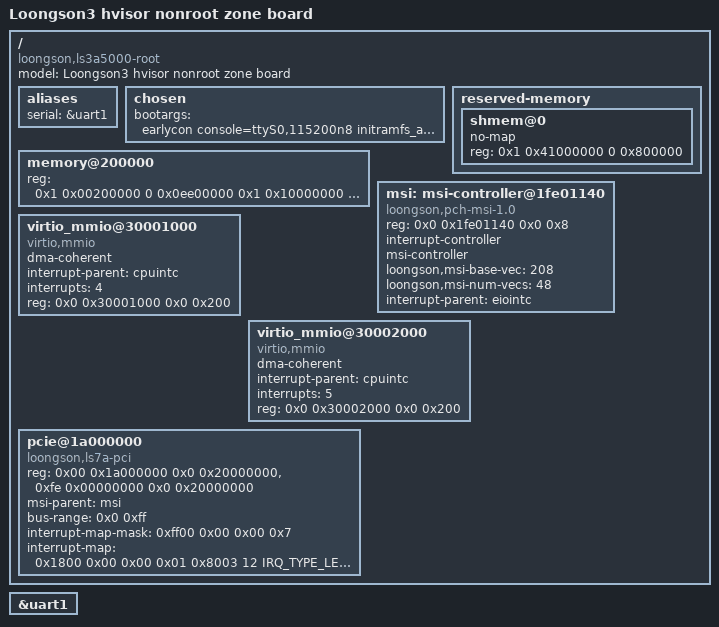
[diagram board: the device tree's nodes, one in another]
// SPDX-License-Identifier: GPL-2.0
/*
* Copyright (C) 2023 Loongson Technology Corporation Limited
* Modified for hvisor by wheatfox(wheatfox17@icloud.com) syswonder.org 2024
*/

/dts-v1/;

#include "loongson-3a5000.dtsi"


&uart1 {
	status = "okay";
	// set the above 'uart1' to 'uart0' if you don't have a COM connection right now
};


/ {
	compatible = "loongson,ls3a5000-root", "loongson,ls3a5000";
	model = "Loongson3 hvisor nonroot zone board";
	
	aliases {
		serial = &uart1;
	};
	
	chosen {
		// initramfs
		bootargs = "earlycon console=ttyS0,115200n8 initramfs_async=false rootwait debug loglevel=8 earlyprintk nohlt";
		
		// SSD root, a {zone_name}-disk.ext4 virtio blk file on SSD root_hvisor partition
		// bootargs = "earlycon console=ttyS0,115200n8 rootwait root=/dev/vda rw";
	};
	
	memory@200000 {
		device_type = "memory";
		reg = <0x1 0x00200000 0 0x0ee00000
		0x1 0x10000000 0 0x10000000
		0x1 0x41000000 0 0x800000
		>;
	};
	
	reserved-memory {
		#address-cells = <0x02>;
		#size-cells = <0x02>;
		ranges;
		shmem@0 {
			no-map;
			reg = <0x1 0x41000000 0 0x800000>;
		};
	};
	
	msi: msi-controller@1fe01140 {
		compatible = "loongson,pch-msi-1.0";
		reg = <0x0 0x1fe01140 0x0 0x8>;
		interrupt-controller;
		#interrupt-cells = <1>;
		msi-controller;
		loongson,msi-base-vec = <208>;
		loongson,msi-num-vecs = <48>;// [64-111(48),112-159(48),160-207(48),208-255(48)]
		interrupt-parent = <&eiointc>;
		phandle = <0x8004>;
	};
	
	// virtio console
	virtio_mmio@30001000 {
		dma-coherent;
		compatible = "virtio,mmio";
		interrupt-parent = <&cpuintc>;
		interrupts = <4>;// = hwirq
		reg = <0x0 0x30001000 0x0 0x200>;
		status = "okay";
	};
	// virtio blk
	virtio_mmio@30002000 {
		dma-coherent;
		compatible = "virtio,mmio";
		// interrupt-parent = <&cpuintc>;
		// interrupts = <5>;// = hwirq
		interrupt-parent = <&cpuintc>;
		interrupts = <5>;// = hwirq
		reg = <0x0 0x30002000 0x0 0x200>;
		status = "okay";
	};
	
	pcie@1a000000 {
		compatible = "loongson,ls7a-pci";
	
		// configuration space
		reg =
		<0x00 0x1a000000 0x0 0x20000000>,
		<0xfe 0x00000000 0x0 0x20000000>;
	
		#address-cells = <3>;
		#size-cells = <2>;
		device_type = "pci";
		msi-parent = <&msi>;
		bus-range = <0x0 0xff>;
	
		// PCIe resources
		ranges =
		<0x01000000 0x0 0x00008000 0x0 0x18408000 0x0 0x00008000>,// 0x01000000 (IO) [PCIe space base address][CPU space address][size]
		<0x02000000 0x0 0x60000000 0x0 0x60000000 0x0 0x20000000>;// 0x02000000 (MEM) [PCIe space base address][CPU space address][size]
	
		// interrputs
		interrupt-map-mask = <0xff00 0x00 0x00 0x7>;
		interrupt-map =
		<
		0x1800 0x00 0x00 0x01 0x8003 12 IRQ_TYPE_LEVEL_HIGH// 3,0 a
		0x1800 0x00 0x00 0x02 0x8003 13 IRQ_TYPE_LEVEL_HIGH// 3,0 b
	
		0x2000 0x00 0x00 0x01 0x8003 49 IRQ_TYPE_LEVEL_HIGH// 4,0 a 
		0x2100 0x00 0x00 0x01 0x8003 48 IRQ_TYPE_LEVEL_HIGH// 4,1 b 
	
		0x2800 0x00 0x00 0x01 0x8003 51 IRQ_TYPE_LEVEL_HIGH// 5,0 a 
		0x2800 0x00 0x00 0x02 0x8003 51 IRQ_TYPE_LEVEL_HIGH// 5,0 b
		0x2800 0x00 0x00 0x03 0x8003 51 IRQ_TYPE_LEVEL_HIGH// 5,0 c 
		0x2800 0x00 0x00 0x04 0x8003 51 IRQ_TYPE_LEVEL_HIGH// 5,0 d 
	
		0x2900 0x00 0x00 0x01 0x8003 50 IRQ_TYPE_LEVEL_HIGH// 5,1 a 
		0x2900 0x00 0x00 0x02 0x8003 50 IRQ_TYPE_LEVEL_HIGH// 5,1 b 
		0x2900 0x00 0x00 0x03 0x8003 50 IRQ_TYPE_LEVEL_HIGH// 5,1 c 
		0x2900 0x00 0x00 0x04 0x8003 50 IRQ_TYPE_LEVEL_HIGH// 5,1 d 
	
		0x3000 0x00 0x00 0x01 0x8003 29 IRQ_TYPE_LEVEL_HIGH// 6,0 a 
		0x3000 0x00 0x00 0x02 0x8003 29 IRQ_TYPE_LEVEL_HIGH// 6,0 b  
		0x3000 0x00 0x00 0x03 0x8003 29 IRQ_TYPE_LEVEL_HIGH// 6,0 c 
		0x3000 0x00 0x00 0x04 0x8003 29 IRQ_TYPE_LEVEL_HIGH// 6,0 d 
	
		0x3100 0x00 0x00 0x01 0x8003 28 IRQ_TYPE_LEVEL_HIGH// 6,1 a
		0x3100 0x00 0x00 0x02 0x8003 28 IRQ_TYPE_LEVEL_HIGH// 6,1 b
		0x3100 0x00 0x00 0x03 0x8003 28 IRQ_TYPE_LEVEL_HIGH// 6,1 c
		0x3100 0x00 0x00 0x04 0x8003 28 IRQ_TYPE_LEVEL_HIGH// 6,1 d
	
		0x3200 0x00 0x00 0x01 0x8003 23 IRQ_TYPE_LEVEL_HIGH// 6,2 a 
		0x3200 0x00 0x00 0x02 0x8003 23 IRQ_TYPE_LEVEL_HIGH// 6,2 b 
		0x3200 0x00 0x00 0x03 0x8003 23 IRQ_TYPE_LEVEL_HIGH// 6,2 c 
		0x3200 0x00 0x00 0x04 0x8003 23 IRQ_TYPE_LEVEL_HIGH// 6,2 d 
	
		0x3800 0x00 0x00 0x01 0x8003 78 IRQ_TYPE_LEVEL_HIGH// 7,0 a
		0x3800 0x00 0x00 0x02 0x8003 79 IRQ_TYPE_LEVEL_HIGH// 7,0 b
	
		0x4000 0x00 0x00 0x01 0x8003 16 IRQ_TYPE_LEVEL_HIGH// 8,0 a 
		0x4000 0x00 0x00 0x02 0x8003 16 IRQ_TYPE_LEVEL_HIGH// 8,0 b 
		0x4000 0x00 0x00 0x03 0x8003 16 IRQ_TYPE_LEVEL_HIGH// 8,0 c 
		0x4000 0x00 0x00 0x04 0x8003 16 IRQ_TYPE_LEVEL_HIGH// 8,0 d 
	
		0x4800 0x00 0x00 0x01 0x8003 32 IRQ_TYPE_LEVEL_HIGH// 9,0 a
		0x4800 0x00 0x00 0x02 0x8003 32 IRQ_TYPE_LEVEL_HIGH// 9,0 b
		0x4800 0x00 0x00 0x03 0x8003 32 IRQ_TYPE_LEVEL_HIGH// 9,0 c 
		0x4800 0x00 0x00 0x04 0x8003 32 IRQ_TYPE_LEVEL_HIGH// 9,0 d
	
		0x5000 0x00 0x00 0x01 0x8003 33 IRQ_TYPE_LEVEL_HIGH// a,0 a 
		0x5000 0x00 0x00 0x02 0x8003 33 IRQ_TYPE_LEVEL_HIGH// a,0 b  
		0x5000 0x00 0x00 0x03 0x8003 33 IRQ_TYPE_LEVEL_HIGH// a,0 c 
		0x5000 0x00 0x00 0x04 0x8003 33 IRQ_TYPE_LEVEL_HIGH// a,0 d 
	
		0x5800 0x00 0x00 0x01 0x8003 34 IRQ_TYPE_LEVEL_HIGH// b,0 a 
		0x5800 0x00 0x00 0x02 0x8003 34 IRQ_TYPE_LEVEL_HIGH// b,0 b 
		0x5800 0x00 0x00 0x03 0x8003 34 IRQ_TYPE_LEVEL_HIGH// b,0 c 
		0x5800 0x00 0x00 0x04 0x8003 34 IRQ_TYPE_LEVEL_HIGH// b,0 d 
	
		0x6000 0x00 0x00 0x01 0x8003 35 IRQ_TYPE_LEVEL_HIGH// c,0 a 
		0x6000 0x00 0x00 0x02 0x8003 35 IRQ_TYPE_LEVEL_HIGH// c,0 b 
		0x6000 0x00 0x00 0x03 0x8003 35 IRQ_TYPE_LEVEL_HIGH// c,0 c 
		0x6000 0x00 0x00 0x04 0x8003 35 IRQ_TYPE_LEVEL_HIGH// c,0 d 
	
		0x6800 0x00 0x00 0x01 0x8003 36 IRQ_TYPE_LEVEL_HIGH// d,0 a 
		0x6800 0x00 0x00 0x02 0x8003 36 IRQ_TYPE_LEVEL_HIGH// d,0 b 
		0x6800 0x00 0x00 0x03 0x8003 36 IRQ_TYPE_LEVEL_HIGH// d,0 c 
		0x6800 0x00 0x00 0x04 0x8003 36 IRQ_TYPE_LEVEL_HIGH// d,0 d 
	
		0x7000 0x00 0x00 0x01 0x8003 37 IRQ_TYPE_LEVEL_HIGH// e,0 a 
		0x7000 0x00 0x00 0x02 0x8003 37 IRQ_TYPE_LEVEL_HIGH// e,0 b 
		0x7000 0x00 0x00 0x03 0x8003 37 IRQ_TYPE_LEVEL_HIGH// e,0 c 
		0x7000 0x00 0x00 0x04 0x8003 37 IRQ_TYPE_LEVEL_HIGH// e,0 d 
	
		0x7800 0x00 0x00 0x01 0x8003 40 IRQ_TYPE_LEVEL_HIGH// f,0 a 
		0x7800 0x00 0x00 0x02 0x8003 40 IRQ_TYPE_LEVEL_HIGH// f,0 b 
		0x7800 0x00 0x00 0x03 0x8003 40 IRQ_TYPE_LEVEL_HIGH// f,0 c 
		0x7800 0x00 0x00 0x04 0x8003 40 IRQ_TYPE_LEVEL_HIGH// f,0 d 
	
		0x8000 0x00 0x00 0x01 0x8003 41 IRQ_TYPE_LEVEL_HIGH// 10,0 a 
		0x8000 0x00 0x00 0x02 0x8003 41 IRQ_TYPE_LEVEL_HIGH// 10,0 b 
		0x8000 0x00 0x00 0x03 0x8003 41 IRQ_TYPE_LEVEL_HIGH// 10,0 c 
		0x8000 0x00 0x00 0x04 0x8003 41 IRQ_TYPE_LEVEL_HIGH// 10,0 d 
	
		0x9800 0x00 0x00 0x01 0x8003 38 IRQ_TYPE_LEVEL_HIGH// 13,0 a
		0x9800 0x00 0x00 0x02 0x8003 38 IRQ_TYPE_LEVEL_HIGH// 13,0 b
		0x9800 0x00 0x00 0x03 0x8003 38 IRQ_TYPE_LEVEL_HIGH// 13,0 c
		0x9800 0x00 0x00 0x04 0x8003 38 IRQ_TYPE_LEVEL_HIGH// 13,0 d
	
		0xa000 0x00 0x00 0x01 0x8003 39 IRQ_TYPE_LEVEL_HIGH// 14,0 a 
		0xa000 0x00 0x00 0x02 0x8003 39 IRQ_TYPE_LEVEL_HIGH// 14,0 b 
		0xa000 0x00 0x00 0x03 0x8003 39 IRQ_TYPE_LEVEL_HIGH// 14,0 c 
		0xa000 0x00 0x00 0x04 0x8003 39 IRQ_TYPE_LEVEL_HIGH// 14,0 d 
	
		0xb800 0x00 0x00 0x01 0x8003 19 IRQ_TYPE_LEVEL_HIGH// 17,0 a 
		0xb800 0x00 0x00 0x02 0x8003 19 IRQ_TYPE_LEVEL_HIGH// 17,0 b 
		0xb800 0x00 0x00 0x03 0x8003 19 IRQ_TYPE_LEVEL_HIGH// 17,0 c 
		0xb800 0x00 0x00 0x04 0x8003 19 IRQ_TYPE_LEVEL_HIGH// 17,0 d 
	
		0xc800 0x00 0x00 0x01 0x8003 22 IRQ_TYPE_LEVEL_HIGH// 19,0 a 
		0xc800 0x00 0x00 0x02 0x8003 22 IRQ_TYPE_LEVEL_HIGH// 19,0 b 
		0xc800 0x00 0x00 0x03 0x8003 22 IRQ_TYPE_LEVEL_HIGH// 19,0 c 
		0xc800 0x00 0x00 0x04 0x8003 22 IRQ_TYPE_LEVEL_HIGH// 19,0 d 
		>;
	
		#interrupt-cells = <0x01>;
	};
};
